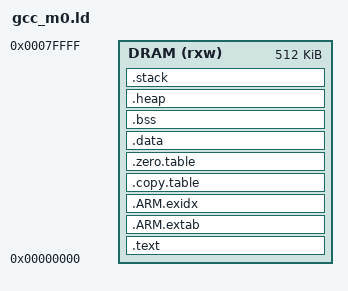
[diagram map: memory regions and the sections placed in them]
MEMORY
{
    DRAM(rxw) : ORIGIN = 0x00000000, LENGTH = 512K
}

__STACK_SIZE = 0x00000400;

/* Linker script to place sections and symbol values. Should be used together
 * with other linker script that defines memory regions FLASH and RAM.
 * It references following symbols, which must be defined in code:
 *   Reset_Handler : Entry of reset handler
 *
 * It defines following symbols, which code can use without definition:
 *   __exidx_start
 *   __exidx_end
 *   __copy_table_start__
 *   __copy_table_end__
 *   __zero_table_start__
 *   __zero_table_end__
 *   __etext
 *   __data_start__
 *   __preinit_array_start
 *   __preinit_array_end
 *   __init_array_start
 *   __init_array_end
 *   __fini_array_start
 *   __fini_array_end
 *   __data_end__
 *   __bss_start__
 *   __bss_end__
 *   __end__
 *   end
 *   __HeapLimit
 *   __StackLimit
 *   __StackTop
 *   __stack
 */
ENTRY(Reset_Handler)

SECTIONS
{
  .text :
  {
    KEEP(*(.vectors))
    *(.text*)

    KEEP(*(.init))
    KEEP(*(.fini))

    /* .ctors */
    PROVIDE(__ctors_start__ = .);
    *crtbegin.o(.ctors)
    *crtbegin?.o(.ctors)
    *(EXCLUDE_FILE(*crtend?.o *crtend.o) .ctors)
    *(SORT(.ctors.*))
    *(.ctors)

    /* .dtors */
    *crtbegin.o(.dtors)
    *crtbegin?.o(.dtors)
    *(EXCLUDE_FILE(*crtend?.o *crtend.o) .dtors)
    *(SORT(.dtors.*))
    *(.dtors)

    *(.rodata*)

    /* section information for finsh shell */
    . = ALIGN(4);
    __fsymtab_start = .;
    KEEP(*(FSymTab))
    __fsymtab_end = .;
    . = ALIGN(4);
    __vsymtab_start = .;
    KEEP(*(VSymTab))
    __vsymtab_end = .;
    . = ALIGN(4);

    /* section information for initial. */
    . = ALIGN(4);
    __rt_init_start = .;
    KEEP(*(SORT(.rti_fn*)))
    __rt_init_end = .;
    . = ALIGN(4);

    /* section information for modules */
    . = ALIGN(4);
    __rtmsymtab_start = .;
    KEEP(*(RTMSymTab))
    __rtmsymtab_end = .;
    . = ALIGN(4);

    KEEP(*(.eh_frame*))
  } > DRAM

  .ARM.extab :
  {
    *(.ARM.extab* .gnu.linkonce.armextab.*)
  } > DRAM

  __exidx_start = .;
  .ARM.exidx :
  {
    *(.ARM.exidx* .gnu.linkonce.armexidx.*)
  } > DRAM
  __exidx_end = .;

  .copy.table :
  {
    . = ALIGN(4);
    __copy_table_start__ = .;
    __copy_table_end__ = .;
  } > DRAM

  .zero.table :
  {
    . = ALIGN(4);
    __zero_table_start__ = .;
    LONG (__bss_start__)
    LONG (__bss_end__ - __bss_start__)
    __zero_table_end__ = .;
  } > DRAM

  /**
   * Location counter can end up 2byte aligned with narrow Thumb code but
   * __etext is assumed by startup code to be the LMA of a section in RAM
   * which must be 4byte aligned
   */
  __etext = ALIGN (4);

  .data :
  {
    __data_start__ = .;
    *(vtable)
    *(.data)
    *(.data.*)

    . = ALIGN(4);
    /* preinit data */
    PROVIDE_HIDDEN (__preinit_array_start = .);
    KEEP(*(.preinit_array))
    PROVIDE_HIDDEN (__preinit_array_end = .);

    . = ALIGN(4);
    /* init data */
    PROVIDE_HIDDEN (__init_array_start = .);
    KEEP(*(SORT(.init_array.*)))
    KEEP(*(.init_array))
    PROVIDE_HIDDEN (__init_array_end = .);


    . = ALIGN(4);
    /* finit data */
    PROVIDE_HIDDEN (__fini_array_start = .);
    KEEP(*(SORT(.fini_array.*)))
    KEEP(*(.fini_array))
    PROVIDE_HIDDEN (__fini_array_end = .);

    KEEP(*(.jcr*))
    . = ALIGN(4);
    /* All data end */
    __data_end__ = .;

  } > DRAM


  .bss :
  {
    . = ALIGN(4);
    __bss_start__ = .;
    *(.bss)
    *(.bss.*)
    *(COMMON)
    . = ALIGN(4);
    __bss_end__ = .;
  } > DRAM


  .heap (COPY) :
  {
    . = ALIGN(8);
    __end__ = .;
    PROVIDE(end = .);
    PROVIDE(__heap_start = .);
    . = ORIGIN(DRAM) + LENGTH(DRAM) - __STACK_SIZE;
    PROVIDE(__heap_end = .);
    . = ALIGN(8);
    __HeapLimit = .;
  } > DRAM

  .stack (ORIGIN(DRAM) + LENGTH(DRAM) - __STACK_SIZE) (COPY) :
  {
    . = ALIGN(8);
    __StackLimit = .;
    . = . + __STACK_SIZE;
    . = ALIGN(8);
    __StackTop = .;
  } > DRAM
  PROVIDE(__stack = __StackTop);
}
